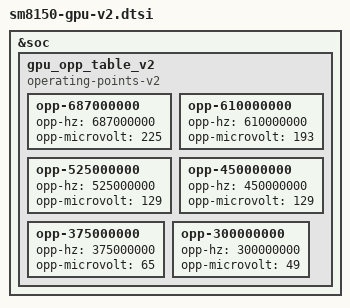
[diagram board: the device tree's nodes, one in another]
/* Copyright (c) 2018-2019, The Linux Foundation. All rights reserved.
 *
 * This program is free software; you can redistribute it and/or modify
 * it under the terms of the GNU General Public License version 2 and
 * only version 2 as published by the Free Software Foundation.
 *
 * This program is distributed in the hope that it will be useful,
 * but WITHOUT ANY WARRANTY; without even the implied warranty of
 * MERCHANTABILITY or FITNESS FOR A PARTICULAR PURPOSE.  See the
 * GNU General Public License for more details.
 */

&soc {
	gpu_opp_table_v2: gpu_opp_table_v2 {
		compatible = "operating-points-v2";

		opp-687000000 {
			opp-hz = /bits/ 64 <687000000>;
			opp-microvolt = <225>;
		};

		opp-610000000 {
			opp-hz = /bits/ 64 <610000000>;
			opp-microvolt = <193>;
		};

		opp-525000000 {
			opp-hz = /bits/ 64 <525000000>;
			opp-microvolt = <129>;
		};

		opp-450000000 {
			opp-hz = /bits/ 64 <450000000>;
			opp-microvolt = <129>;
		};

		opp-375000000 {
			opp-hz = /bits/ 64 <375000000>;
			opp-microvolt = <65>;
		};

		opp-300000000 {
			opp-hz = /bits/ 64 <300000000>;
			opp-microvolt = <49>;
		};
	};
};
